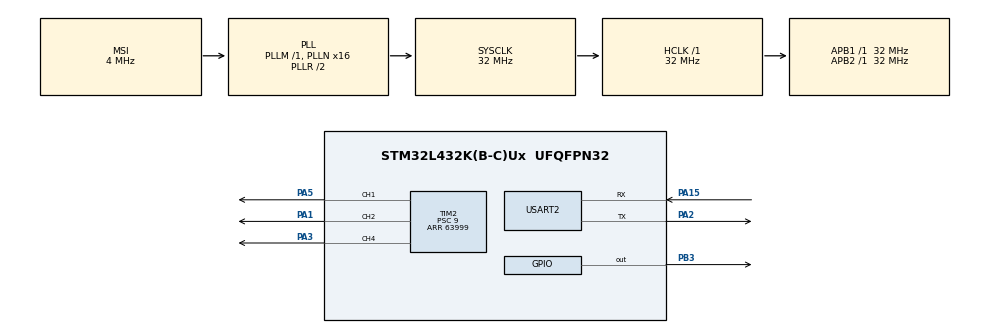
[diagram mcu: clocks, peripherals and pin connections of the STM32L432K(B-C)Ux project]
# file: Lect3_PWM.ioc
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Mcu.Family=STM32L4
Mcu.Name=STM32L432K(B-C)Ux
Mcu.Package=UFQFPN32
NVIC.PriorityGroup=NVIC_PRIORITYGROUP_4
PA0.Mode=HSE-External-Clock-Source-for-LittleOrca
PA0.Signal=RCC_CK_IN
PA1.Signal=S_TIM2_CH2
PA13\ (JTMS-SWDIO).Mode=Serial_Wire
PA13\ (JTMS-SWDIO).Signal=SYS_JTMS-SWDIO
PA14\ (JTCK-SWCLK).Mode=Serial_Wire
PA14\ (JTCK-SWCLK).Signal=SYS_JTCK-SWCLK
PA15\ (JTDI).GPIO_ModeDefaultPP=GPIO_MODE_AF_PP
PA15\ (JTDI).GPIO_PuPd=GPIO_NOPULL
PA15\ (JTDI).GPIO_Speed=GPIO_SPEED_FREQ_VERY_HIGH
PA15\ (JTDI).Mode=Asynchronous
PA15\ (JTDI).Signal=USART2_RX
PA2.GPIO_ModeDefaultPP=GPIO_MODE_AF_PP
PA2.GPIO_PuPd=GPIO_NOPULL
PA2.GPIO_Speed=GPIO_SPEED_FREQ_VERY_HIGH
PA2.Mode=Asynchronous
PA2.Signal=USART2_TX
PA3.Signal=S_TIM2_CH4
PA5.Signal=S_TIM2_CH1
PB3\ (JTDO-TRACESWO).GPIO_ModeDefaultOutputPP=GPIO_MODE_OUTPUT_PP
PB3\ (JTDO-TRACESWO).GPIO_PuPd=GPIO_NOPULL
PB3\ (JTDO-TRACESWO).GPIO_Speed=GPIO_SPEED_FREQ_LOW
PB3\ (JTDO-TRACESWO).PinState=GPIO_PIN_RESET
PB3\ (JTDO-TRACESWO).Signal=GPIO_Output
PC14-OSC32_IN\ (PC14).Mode=LSE-External-Oscillator
PC14-OSC32_IN\ (PC14).Signal=RCC_OSC32_IN
PC15-OSC32_OUT\ (PC15).Mode=LSE-External-Oscillator
PC15-OSC32_OUT\ (PC15).Signal=RCC_OSC32_OUT
ProjectManager.HeapSize=0x200
ProjectManager.StackSize=0x400
ProjectManager.TargetToolchain=STM32CubeIDE
RCC.AHBFreq_Value=32000000
RCC.APB1Freq_Value=32000000
RCC.APB1TimFreq_Value=32000000
RCC.APB2Freq_Value=32000000
RCC.APB2TimFreq_Value=32000000
RCC.CortexFreq_Value=32000000
RCC.HCLKFreq_Value=32000000
RCC.HSE_VALUE=8000000
RCC.HSI48_VALUE=48000000
RCC.HSI_VALUE=16000000
RCC.MSI_VALUE=4000000
RCC.PLLN=16
RCC.SYSCLKFreq_VALUE=32000000
RCC.SYSCLKSource=RCC_SYSCLKSOURCE_PLLCLK
RCC.VCOOutputFreq_Value=64000000
SH.S_TIM2_CH1.0=TIM2_CH1,PWM Generation1 CH1
SH.S_TIM2_CH2.0=TIM2_CH2,PWM Generation2 CH2
SH.S_TIM2_CH4.0=TIM2_CH4,PWM Generation4 CH4
TIM2.Channel-PWM\ Generation1\ CH1=TIM_CHANNEL_1
TIM2.Channel-PWM\ Generation2\ CH2=TIM_CHANNEL_2
TIM2.Channel-PWM\ Generation4\ CH4=TIM_CHANNEL_4
TIM2.Period=63999
TIM2.Prescaler=9
TIM2.Pulse-PWM\ Generation1\ CH1=3199
TIM2.Pulse-PWM\ Generation2\ CH2=4699
TIM2.Pulse-PWM\ Generation4\ CH4=6199
USART2.VirtualMode-Asynchronous=VM_ASYNC
VP_TIM16_VS_ClockSourceINT.Mode=Enable_Timer
VP_TIM2_VS_ClockSourceINT.Mode=Internal
board=NUCLEO-L432KC

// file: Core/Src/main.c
/* USER CODE BEGIN Header */
/**
  ******************************************************************************
  * @file           : main.c
  * @brief          : Main program body
  ******************************************************************************
  * @attention
  *
  * <h2><center>&copy; Copyright (c) 2020 STMicroelectronics.
  * All rights reserved.</center></h2>
  *
  * This software component is licensed by ST under BSD 3-Clause license,
  * the "License"; You may not use this file except in compliance with the
  * License. You may obtain a copy of the License at:
  *                        opensource.org/licenses/BSD-3-Clause
  *
  ******************************************************************************
  */
/* USER CODE END Header */
#include "main.h"

TIM_HandleTypeDef htim2;
TIM_HandleTypeDef htim16;

UART_HandleTypeDef huart2;

void SystemClock_Config(void);
static void MX_GPIO_Init(void);
static void MX_USART2_UART_Init(void);
static void MX_TIM2_Init(void);
static void MX_TIM16_Init(void);

int main(void)
{

  /* MCU Configuration--------------------------------------------------------*/

  /* Reset of all peripherals, Initializes the Flash interface and the Systick. */
  HAL_Init();

  /* Configure the system clock */
  SystemClock_Config();

  /* Initialize all configured peripherals */
  MX_GPIO_Init();
  MX_USART2_UART_Init();
  MX_TIM2_Init();
  MX_TIM16_Init();

  /* Infinite loop */
  /* USER CODE BEGIN WHILE */
  HAL_TIM_PWM_Start(&htim2,  TIM_CHANNEL_2);
  HAL_TIM_PWM_Start(&htim2,  TIM_CHANNEL_1);
  HAL_TIM_PWM_Start(&htim2,  TIM_CHANNEL_4);

// To adjust PWM duty cycle, need to change value in CCRx register
//  TIM2->CCR1 = 12196;
//     or
//  __HAL_TIM_SET_COMPARE(&htim2, TIM_CHANNEL_1,12196);

  while (1)
  {
    /* USER CODE END WHILE */

  }
}

void SystemClock_Config(void)
{
  RCC_OscInitTypeDef RCC_OscInitStruct = {0};
  RCC_ClkInitTypeDef RCC_ClkInitStruct = {0};
  RCC_PeriphCLKInitTypeDef PeriphClkInit = {0};

  /** Configure LSE Drive Capability
  */
  HAL_PWR_EnableBkUpAccess();
  __HAL_RCC_LSEDRIVE_CONFIG(RCC_LSEDRIVE_LOW);
  /** Initializes the RCC Oscillators according to the specified parameters
  * in the RCC_OscInitTypeDef structure.
  */
  RCC_OscInitStruct.OscillatorType = RCC_OSCILLATORTYPE_LSE|RCC_OSCILLATORTYPE_MSI;
  RCC_OscInitStruct.LSEState = RCC_LSE_ON;
  RCC_OscInitStruct.MSIState = RCC_MSI_ON;
  RCC_OscInitStruct.MSICalibrationValue = 0;
  RCC_OscInitStruct.MSIClockRange = RCC_MSIRANGE_6;
  RCC_OscInitStruct.PLL.PLLState = RCC_PLL_ON;
  RCC_OscInitStruct.PLL.PLLSource = RCC_PLLSOURCE_MSI;
  RCC_OscInitStruct.PLL.PLLM = 1;
  RCC_OscInitStruct.PLL.PLLN = 16;
  RCC_OscInitStruct.PLL.PLLP = RCC_PLLP_DIV7;
  RCC_OscInitStruct.PLL.PLLQ = RCC_PLLQ_DIV2;
  RCC_OscInitStruct.PLL.PLLR = RCC_PLLR_DIV2;
  if (HAL_RCC_OscConfig(&RCC_OscInitStruct) != HAL_OK)
  {
    Error_Handler();
  }
  /** Initializes the CPU, AHB and APB buses clocks
  */
  RCC_ClkInitStruct.ClockType = RCC_CLOCKTYPE_HCLK|RCC_CLOCKTYPE_SYSCLK
                              |RCC_CLOCKTYPE_PCLK1|RCC_CLOCKTYPE_PCLK2;
  RCC_ClkInitStruct.SYSCLKSource = RCC_SYSCLKSOURCE_PLLCLK;
  RCC_ClkInitStruct.AHBCLKDivider = RCC_SYSCLK_DIV1;
  RCC_ClkInitStruct.APB1CLKDivider = RCC_HCLK_DIV1;
  RCC_ClkInitStruct.APB2CLKDivider = RCC_HCLK_DIV1;

  if (HAL_RCC_ClockConfig(&RCC_ClkInitStruct, FLASH_LATENCY_1) != HAL_OK)
  {
    Error_Handler();
  }
  PeriphClkInit.PeriphClockSelection = RCC_PERIPHCLK_USART2;
  PeriphClkInit.Usart2ClockSelection = RCC_USART2CLKSOURCE_PCLK1;
  if (HAL_RCCEx_PeriphCLKConfig(&PeriphClkInit) != HAL_OK)
  {
    Error_Handler();
  }
  /** Configure the main internal regulator output voltage
  */
  if (HAL_PWREx_ControlVoltageScaling(PWR_REGULATOR_VOLTAGE_SCALE1) != HAL_OK)
  {
    Error_Handler();
  }
  /** Enable MSI Auto calibration
  */
  HAL_RCCEx_EnableMSIPLLMode();
}

static void MX_TIM2_Init(void)
{

  TIM_ClockConfigTypeDef sClockSourceConfig = {0};
  TIM_MasterConfigTypeDef sMasterConfig = {0};
  TIM_OC_InitTypeDef sConfigOC = {0};

  htim2.Instance = TIM2;
  htim2.Init.Prescaler = 9;
  htim2.Init.CounterMode = TIM_COUNTERMODE_UP;
  htim2.Init.Period = 63999;
  htim2.Init.ClockDivision = TIM_CLOCKDIVISION_DIV1;
  htim2.Init.AutoReloadPreload = TIM_AUTORELOAD_PRELOAD_DISABLE;
  if (HAL_TIM_Base_Init(&htim2) != HAL_OK)
  {
    Error_Handler();
  }
  sClockSourceConfig.ClockSource = TIM_CLOCKSOURCE_INTERNAL;
  if (HAL_TIM_ConfigClockSource(&htim2, &sClockSourceConfig) != HAL_OK)
  {
    Error_Handler();
  }
  if (HAL_TIM_PWM_Init(&htim2) != HAL_OK)
  {
    Error_Handler();
  }
  sMasterConfig.MasterOutputTrigger = TIM_TRGO_RESET;
  sMasterConfig.MasterSlaveMode = TIM_MASTERSLAVEMODE_DISABLE;
  if (HAL_TIMEx_MasterConfigSynchronization(&htim2, &sMasterConfig) != HAL_OK)
  {
    Error_Handler();
  }
  sConfigOC.OCMode = TIM_OCMODE_PWM1;
  sConfigOC.Pulse = 3199;
  sConfigOC.OCPolarity = TIM_OCPOLARITY_HIGH;
  sConfigOC.OCFastMode = TIM_OCFAST_DISABLE;
  if (HAL_TIM_PWM_ConfigChannel(&htim2, &sConfigOC, TIM_CHANNEL_1) != HAL_OK)
  {
    Error_Handler();
  }
  sConfigOC.Pulse = 4699;
  if (HAL_TIM_PWM_ConfigChannel(&htim2, &sConfigOC, TIM_CHANNEL_2) != HAL_OK)
  {
    Error_Handler();
  }
  sConfigOC.Pulse = 6199;
  if (HAL_TIM_PWM_ConfigChannel(&htim2, &sConfigOC, TIM_CHANNEL_4) != HAL_OK)
  {
    Error_Handler();
  }
  HAL_TIM_MspPostInit(&htim2);

}

static void MX_TIM16_Init(void)
{

  htim16.Instance = TIM16;
  htim16.Init.Prescaler = 0;
  htim16.Init.CounterMode = TIM_COUNTERMODE_UP;
  htim16.Init.Period = 65535;
  htim16.Init.ClockDivision = TIM_CLOCKDIVISION_DIV1;
  htim16.Init.RepetitionCounter = 0;
  htim16.Init.AutoReloadPreload = TIM_AUTORELOAD_PRELOAD_DISABLE;
  if (HAL_TIM_Base_Init(&htim16) != HAL_OK)
  {
    Error_Handler();
  }

}

static void MX_USART2_UART_Init(void)
{

  huart2.Instance = USART2;
  huart2.Init.BaudRate = 115200;
  huart2.Init.WordLength = UART_WORDLENGTH_8B;
  huart2.Init.StopBits = UART_STOPBITS_1;
  huart2.Init.Parity = UART_PARITY_NONE;
  huart2.Init.Mode = UART_MODE_TX_RX;
  huart2.Init.HwFlowCtl = UART_HWCONTROL_NONE;
  huart2.Init.OverSampling = UART_OVERSAMPLING_16;
  huart2.Init.OneBitSampling = UART_ONE_BIT_SAMPLE_DISABLE;
  huart2.AdvancedInit.AdvFeatureInit = UART_ADVFEATURE_NO_INIT;
  if (HAL_UART_Init(&huart2) != HAL_OK)
  {
    Error_Handler();
  }

}

static void MX_GPIO_Init(void)
{
  GPIO_InitTypeDef GPIO_InitStruct = {0};

  /* GPIO Ports Clock Enable */
  __HAL_RCC_GPIOC_CLK_ENABLE();
  __HAL_RCC_GPIOA_CLK_ENABLE();
  __HAL_RCC_GPIOB_CLK_ENABLE();

  /*Configure GPIO pin Output Level */
  HAL_GPIO_WritePin(GPIOB, GPIO_PIN_3, GPIO_PIN_RESET);

  /*Configure GPIO pin : PB3 */
  GPIO_InitStruct.Pin = GPIO_PIN_3;
  GPIO_InitStruct.Mode = GPIO_MODE_OUTPUT_PP;
  GPIO_InitStruct.Pull = GPIO_NOPULL;
  GPIO_InitStruct.Speed = GPIO_SPEED_FREQ_LOW;
  HAL_GPIO_Init(GPIOB, &GPIO_InitStruct);

}

void Error_Handler(void)
{
}

/************************ (C) COPYRIGHT STMicroelectronics *****END OF FILE****/
